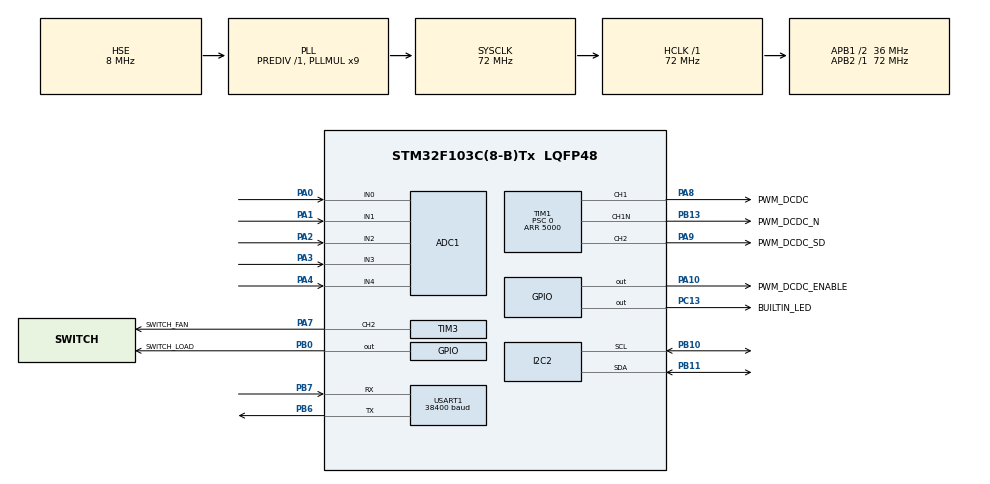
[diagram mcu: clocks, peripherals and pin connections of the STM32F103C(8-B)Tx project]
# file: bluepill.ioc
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ADC1.Channel-2\#ChannelRegularConversion=ADC_CHANNEL_0
ADC1.Channel-3\#ChannelRegularConversion=ADC_CHANNEL_1
ADC1.Channel-4\#ChannelRegularConversion=ADC_CHANNEL_2
ADC1.Channel-5\#ChannelRegularConversion=ADC_CHANNEL_3
ADC1.Channel-6\#ChannelRegularConversion=ADC_CHANNEL_4
ADC1.ContinuousConvMode=ENABLE
ADC1.NbrOfConversion=5
ADC1.NbrOfConversionFlag=1
ADC1.Rank-2\#ChannelRegularConversion=1
ADC1.Rank-3\#ChannelRegularConversion=2
ADC1.Rank-4\#ChannelRegularConversion=3
ADC1.Rank-5\#ChannelRegularConversion=4
ADC1.Rank-6\#ChannelRegularConversion=5
ADC1.SamplingTime-2\#ChannelRegularConversion=ADC_SAMPLETIME_239CYCLES_5
ADC1.SamplingTime-3\#ChannelRegularConversion=ADC_SAMPLETIME_239CYCLES_5
ADC1.SamplingTime-4\#ChannelRegularConversion=ADC_SAMPLETIME_239CYCLES_5
ADC1.SamplingTime-5\#ChannelRegularConversion=ADC_SAMPLETIME_239CYCLES_5
ADC1.SamplingTime-6\#ChannelRegularConversion=ADC_SAMPLETIME_239CYCLES_5
ADC1.master=1
Dma.ADC1.0.Direction=DMA_PERIPH_TO_MEMORY
Dma.ADC1.0.Instance=DMA1_Channel1
Dma.ADC1.0.MemDataAlignment=DMA_MDATAALIGN_HALFWORD
Dma.ADC1.0.MemInc=DMA_MINC_ENABLE
Dma.ADC1.0.Mode=DMA_CIRCULAR
Dma.ADC1.0.PeriphDataAlignment=DMA_PDATAALIGN_HALFWORD
Dma.ADC1.0.PeriphInc=DMA_PINC_DISABLE
Dma.ADC1.0.Priority=DMA_PRIORITY_LOW
Dma.Request0=ADC1
Mcu.Family=STM32F1
Mcu.Name=STM32F103C(8-B)Tx
Mcu.Package=LQFP48
NVIC.DMA1_Channel1_IRQn=true\:0\:0\:false\:false\:true\:false\:true\:true
NVIC.PriorityGroup=NVIC_PRIORITYGROUP_4
NVIC.TIM2_IRQn=true\:0\:0\:false\:false\:true\:true\:true\:true
NVIC.USART1_IRQn=true\:0\:0\:false\:false\:true\:true\:true\:true
PA0-WKUP.Signal=ADCx_IN0
PA1.Signal=ADCx_IN1
PA10.GPIO_Label=PWM_DCDC_ENABLE
PA10.Signal=GPIO_Output
PA13.Mode=Serial_Wire
PA13.Signal=SYS_JTMS-SWDIO
PA14.Mode=Serial_Wire
PA14.Signal=SYS_JTCK-SWCLK
PA2.Signal=ADCx_IN2
PA3.Signal=ADCx_IN3
PA4.Signal=ADCx_IN4
PA7.GPIO_Label=SWITCH_FAN
PA7.Signal=S_TIM3_CH2
PA8.GPIO_Label=PWM_DCDC
PA8.Signal=S_TIM1_CH1
PA9.GPIO_Label=PWM_DCDC_SD
PA9.Signal=S_TIM1_CH2
PB0.GPIO_Label=SWITCH_LOAD
PB0.Signal=GPIO_Output
PB10.GPIO_Pu=GPIO_PULLUP
PB10.Mode=I2C
PB10.Signal=I2C2_SCL
PB11.GPIO_Pu=GPIO_PULLUP
PB11.Mode=I2C
PB11.Signal=I2C2_SDA
PB13.GPIO_Label=PWM_DCDC_N
PB13.Mode=PWM Generation1 CH1 CH1N
PB13.Signal=TIM1_CH1N
PB6.Mode=Asynchronous
PB6.Signal=USART1_TX
PB7.Mode=Asynchronous
PB7.Signal=USART1_RX
PC13-TAMPER-RTC.GPIO_Label=BUILTIN_LED
PC13-TAMPER-RTC.Signal=GPIO_Output
PC14-OSC32_IN.Mode=LSE-External-Oscillator
PC14-OSC32_IN.Signal=RCC_OSC32_IN
PC15-OSC32_OUT.Mode=LSE-External-Oscillator
PC15-OSC32_OUT.Signal=RCC_OSC32_OUT
PD0-OSC_IN.Mode=HSE-External-Oscillator
PD0-OSC_IN.Signal=RCC_OSC_IN
PD1-OSC_OUT.Mode=HSE-External-Oscillator
PD1-OSC_OUT.Signal=RCC_OSC_OUT
ProjectManager.HeapSize=0x200
ProjectManager.StackSize=0x400
ProjectManager.TargetToolchain=Makefile
RCC.ADCPresc=RCC_ADCPCLK2_DIV6
RCC.AHBFreq_Value=72000000
RCC.APB1CLKDivider=RCC_HCLK_DIV2
RCC.APB1Freq_Value=36000000
RCC.APB1TimFreq_Value=72000000
RCC.APB2Freq_Value=72000000
RCC.APB2TimFreq_Value=72000000
RCC.HCLKFreq_Value=72000000
RCC.PLLMUL=RCC_PLL_MUL9
RCC.PLLSourceVirtual=RCC_PLLSOURCE_HSE
RCC.RTCClockSelection=RCC_RTCCLKSOURCE_LSE
RCC.SYSCLKFreq_VALUE=72000000
RCC.SYSCLKSource=RCC_SYSCLKSOURCE_PLLCLK
RCC.USBFreq_Value=48000000
RCC.USBPrescaler=RCC_USBCLKSOURCE_PLL_DIV1_5
SH.ADCx_IN0.0=ADC1_IN0,IN0
SH.ADCx_IN1.0=ADC1_IN1,IN1
SH.ADCx_IN2.0=ADC1_IN2,IN2
SH.ADCx_IN3.0=ADC1_IN3,IN3
SH.ADCx_IN4.0=ADC1_IN4,IN4
SH.S_TIM1_CH1.0=TIM1_CH1,PWM Generation1 CH1 CH1N
SH.S_TIM1_CH2.0=TIM1_CH2,PWM Generation2 CH2
SH.S_TIM3_CH2.0=TIM3_CH2,PWM Generation2 CH2
TIM1.AutomaticOutput=TIM_AUTOMATICOUTPUT_DISABLE
TIM1.Channel-PWM\ Generation1\ CH1\ CH1N=TIM_CHANNEL_1
TIM1.Channel-PWM\ Generation2\ CH2=TIM_CHANNEL_2
TIM1.OCIdleState_1=TIM_OCIDLESTATE_RESET
TIM1.OCPolarity_1=TIM_OCPOLARITY_HIGH
TIM1.Period=5000
TIM1.Prescaler=0
TIM2.Period=20000
TIM2.Prescaler=71
TIM3.Channel-PWM\ Generation2\ CH2=TIM_CHANNEL_2
TIM3.Period=255
USART1.BaudRate=38400
USART1.VirtualMode=VM_ASYNC
VP_RTC_No_RTC_Output.Mode=RTC_OUT_NO
VP_RTC_VS_RTC_Activate.Mode=RTC_Enabled
VP_RTC_VS_RTC_Calendar.Mode=RTC_Calendar
VP_TIM1_VS_ClockSourceINT.Mode=Internal
VP_TIM2_VS_ClockSourceINT.Mode=Internal
VP_TIM3_VS_ClockSourceINT.Mode=Internal
board=custom

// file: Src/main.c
/* USER CODE BEGIN Header */
/**
  ******************************************************************************
  * @file           : main.c
  * @brief          : Main program body
  ******************************************************************************
  * @attention
  *
  * <h2><center>&copy; Copyright (c) 2019 STMicroelectronics.
  * All rights reserved.</center></h2>
  *
  * This software component is licensed by ST under BSD 3-Clause license,
  * the "License"; You may not use this file except in compliance with the
  * License. You may obtain a copy of the License at:
  *                        opensource.org/licenses/BSD-3-Clause
  *
  ******************************************************************************
  */
/* USER CODE END Header */
#include "main.h"

/* USER CODE BEGIN Includes */
#include "solar.h"
/* USER CODE END Includes */

ADC_HandleTypeDef hadc1;
DMA_HandleTypeDef hdma_adc1;

I2C_HandleTypeDef hi2c2;

RTC_HandleTypeDef hrtc;

TIM_HandleTypeDef htim1;
TIM_HandleTypeDef htim2;
TIM_HandleTypeDef htim3;

UART_HandleTypeDef huart1;

void SystemClock_Config(void);
static void MX_GPIO_Init(void);
static void MX_DMA_Init(void);
static void MX_RTC_Init(void);
static void MX_USART1_UART_Init(void);
static void MX_ADC1_Init(void);
static void MX_TIM1_Init(void);
static void MX_TIM2_Init(void);
static void MX_I2C2_Init(void);
static void MX_TIM3_Init(void);

int main(void)
{

  /* MCU Configuration--------------------------------------------------------*/

  /* Reset of all peripherals, Initializes the Flash interface and the Systick. */
  HAL_Init();

  /* Configure the system clock */
  SystemClock_Config();

  /* Initialize all configured peripherals */
  MX_GPIO_Init();
  MX_DMA_Init();
  MX_RTC_Init();
  MX_USART1_UART_Init();
  MX_ADC1_Init();
  MX_TIM1_Init();
  MX_TIM2_Init();
  MX_I2C2_Init();
  MX_TIM3_Init();

  /* Infinite loop */
  /* USER CODE BEGIN WHILE */
  solar_main();
  while (1)
  {
    /* USER CODE END WHILE */

  }
}

void SystemClock_Config(void)
{
  RCC_OscInitTypeDef RCC_OscInitStruct = {0};
  RCC_ClkInitTypeDef RCC_ClkInitStruct = {0};
  RCC_PeriphCLKInitTypeDef PeriphClkInit = {0};

  /** Initializes the RCC Oscillators according to the specified parameters
  * in the RCC_OscInitTypeDef structure.
  */
  RCC_OscInitStruct.OscillatorType = RCC_OSCILLATORTYPE_HSE|RCC_OSCILLATORTYPE_LSE;
  RCC_OscInitStruct.HSEState = RCC_HSE_ON;
  RCC_OscInitStruct.HSEPredivValue = RCC_HSE_PREDIV_DIV1;
  RCC_OscInitStruct.LSEState = RCC_LSE_ON;
  RCC_OscInitStruct.HSIState = RCC_HSI_ON;
  RCC_OscInitStruct.PLL.PLLState = RCC_PLL_ON;
  RCC_OscInitStruct.PLL.PLLSource = RCC_PLLSOURCE_HSE;
  RCC_OscInitStruct.PLL.PLLMUL = RCC_PLL_MUL9;
  if (HAL_RCC_OscConfig(&RCC_OscInitStruct) != HAL_OK)
  {
    Error_Handler();
  }

  /** Initializes the CPU, AHB and APB buses clocks
  */
  RCC_ClkInitStruct.ClockType = RCC_CLOCKTYPE_HCLK|RCC_CLOCKTYPE_SYSCLK
                              |RCC_CLOCKTYPE_PCLK1|RCC_CLOCKTYPE_PCLK2;
  RCC_ClkInitStruct.SYSCLKSource = RCC_SYSCLKSOURCE_PLLCLK;
  RCC_ClkInitStruct.AHBCLKDivider = RCC_SYSCLK_DIV1;
  RCC_ClkInitStruct.APB1CLKDivider = RCC_HCLK_DIV2;
  RCC_ClkInitStruct.APB2CLKDivider = RCC_HCLK_DIV1;

  if (HAL_RCC_ClockConfig(&RCC_ClkInitStruct, FLASH_LATENCY_2) != HAL_OK)
  {
    Error_Handler();
  }
  PeriphClkInit.PeriphClockSelection = RCC_PERIPHCLK_RTC|RCC_PERIPHCLK_ADC;
  PeriphClkInit.RTCClockSelection = RCC_RTCCLKSOURCE_LSE;
  PeriphClkInit.AdcClockSelection = RCC_ADCPCLK2_DIV6;
  if (HAL_RCCEx_PeriphCLKConfig(&PeriphClkInit) != HAL_OK)
  {
    Error_Handler();
  }
}

static void MX_ADC1_Init(void)
{

  ADC_ChannelConfTypeDef sConfig = {0};

  /** Common config
  */
  hadc1.Instance = ADC1;
  hadc1.Init.ScanConvMode = ADC_SCAN_ENABLE;
  hadc1.Init.ContinuousConvMode = ENABLE;
  hadc1.Init.DiscontinuousConvMode = DISABLE;
  hadc1.Init.ExternalTrigConv = ADC_SOFTWARE_START;
  hadc1.Init.DataAlign = ADC_DATAALIGN_RIGHT;
  hadc1.Init.NbrOfConversion = 5;
  if (HAL_ADC_Init(&hadc1) != HAL_OK)
  {
    Error_Handler();
  }

  /** Configure Regular Channel
  */
  sConfig.Channel = ADC_CHANNEL_0;
  sConfig.Rank = ADC_REGULAR_RANK_1;
  sConfig.SamplingTime = ADC_SAMPLETIME_239CYCLES_5;
  if (HAL_ADC_ConfigChannel(&hadc1, &sConfig) != HAL_OK)
  {
    Error_Handler();
  }

  /** Configure Regular Channel
  */
  sConfig.Channel = ADC_CHANNEL_1;
  sConfig.Rank = ADC_REGULAR_RANK_2;
  if (HAL_ADC_ConfigChannel(&hadc1, &sConfig) != HAL_OK)
  {
    Error_Handler();
  }

  /** Configure Regular Channel
  */
  sConfig.Channel = ADC_CHANNEL_2;
  sConfig.Rank = ADC_REGULAR_RANK_3;
  if (HAL_ADC_ConfigChannel(&hadc1, &sConfig) != HAL_OK)
  {
    Error_Handler();
  }

  /** Configure Regular Channel
  */
  sConfig.Channel = ADC_CHANNEL_3;
  sConfig.Rank = ADC_REGULAR_RANK_4;
  if (HAL_ADC_ConfigChannel(&hadc1, &sConfig) != HAL_OK)
  {
    Error_Handler();
  }

  /** Configure Regular Channel
  */
  sConfig.Channel = ADC_CHANNEL_4;
  sConfig.Rank = ADC_REGULAR_RANK_5;
  if (HAL_ADC_ConfigChannel(&hadc1, &sConfig) != HAL_OK)
  {
    Error_Handler();
  }

}

static void MX_I2C2_Init(void)
{

  hi2c2.Instance = I2C2;
  hi2c2.Init.ClockSpeed = 100000;
  hi2c2.Init.DutyCycle = I2C_DUTYCYCLE_2;
  hi2c2.Init.OwnAddress1 = 0;
  hi2c2.Init.AddressingMode = I2C_ADDRESSINGMODE_7BIT;
  hi2c2.Init.DualAddressMode = I2C_DUALADDRESS_DISABLE;
  hi2c2.Init.OwnAddress2 = 0;
  hi2c2.Init.GeneralCallMode = I2C_GENERALCALL_DISABLE;
  hi2c2.Init.NoStretchMode = I2C_NOSTRETCH_DISABLE;
  if (HAL_I2C_Init(&hi2c2) != HAL_OK)
  {
    Error_Handler();
  }

}

static void MX_RTC_Init(void)
{

  RTC_TimeTypeDef sTime = {0};
  RTC_DateTypeDef DateToUpdate = {0};

  /** Initialize RTC Only
  */
  hrtc.Instance = RTC;
  hrtc.Init.AsynchPrediv = RTC_AUTO_1_SECOND;
  hrtc.Init.OutPut = RTC_OUTPUTSOURCE_NONE;
  if (HAL_RTC_Init(&hrtc) != HAL_OK)
  {
    Error_Handler();
  }

  /** Initialize RTC and set the Time and Date
  */
  sTime.Hours = 0x0;
  sTime.Minutes = 0x0;
  sTime.Seconds = 0x0;

  if (HAL_RTC_SetTime(&hrtc, &sTime, RTC_FORMAT_BCD) != HAL_OK)
  {
    Error_Handler();
  }
  DateToUpdate.WeekDay = RTC_WEEKDAY_MONDAY;
  DateToUpdate.Month = RTC_MONTH_JANUARY;
  DateToUpdate.Date = 0x1;
  DateToUpdate.Year = 0x0;

  if (HAL_RTC_SetDate(&hrtc, &DateToUpdate, RTC_FORMAT_BCD) != HAL_OK)
  {
    Error_Handler();
  }

}

static void MX_TIM1_Init(void)
{

  TIM_ClockConfigTypeDef sClockSourceConfig = {0};
  TIM_MasterConfigTypeDef sMasterConfig = {0};
  TIM_OC_InitTypeDef sConfigOC = {0};
  TIM_BreakDeadTimeConfigTypeDef sBreakDeadTimeConfig = {0};

  htim1.Instance = TIM1;
  htim1.Init.Prescaler = 0;
  htim1.Init.CounterMode = TIM_COUNTERMODE_UP;
  htim1.Init.Period = 5000;
  htim1.Init.ClockDivision = TIM_CLOCKDIVISION_DIV1;
  htim1.Init.RepetitionCounter = 0;
  htim1.Init.AutoReloadPreload = TIM_AUTORELOAD_PRELOAD_DISABLE;
  if (HAL_TIM_Base_Init(&htim1) != HAL_OK)
  {
    Error_Handler();
  }
  sClockSourceConfig.ClockSource = TIM_CLOCKSOURCE_INTERNAL;
  if (HAL_TIM_ConfigClockSource(&htim1, &sClockSourceConfig) != HAL_OK)
  {
    Error_Handler();
  }
  if (HAL_TIM_PWM_Init(&htim1) != HAL_OK)
  {
    Error_Handler();
  }
  sMasterConfig.MasterOutputTrigger = TIM_TRGO_RESET;
  sMasterConfig.MasterSlaveMode = TIM_MASTERSLAVEMODE_DISABLE;
  if (HAL_TIMEx_MasterConfigSynchronization(&htim1, &sMasterConfig) != HAL_OK)
  {
    Error_Handler();
  }
  sConfigOC.OCMode = TIM_OCMODE_PWM1;
  sConfigOC.Pulse = 0;
  sConfigOC.OCPolarity = TIM_OCPOLARITY_HIGH;
  sConfigOC.OCNPolarity = TIM_OCNPOLARITY_HIGH;
  sConfigOC.OCFastMode = TIM_OCFAST_DISABLE;
  sConfigOC.OCIdleState = TIM_OCIDLESTATE_RESET;
  sConfigOC.OCNIdleState = TIM_OCNIDLESTATE_RESET;
  if (HAL_TIM_PWM_ConfigChannel(&htim1, &sConfigOC, TIM_CHANNEL_1) != HAL_OK)
  {
    Error_Handler();
  }
  if (HAL_TIM_PWM_ConfigChannel(&htim1, &sConfigOC, TIM_CHANNEL_2) != HAL_OK)
  {
    Error_Handler();
  }
  sBreakDeadTimeConfig.OffStateRunMode = TIM_OSSR_DISABLE;
  sBreakDeadTimeConfig.OffStateIDLEMode = TIM_OSSI_DISABLE;
  sBreakDeadTimeConfig.LockLevel = TIM_LOCKLEVEL_OFF;
  sBreakDeadTimeConfig.DeadTime = 0;
  sBreakDeadTimeConfig.BreakState = TIM_BREAK_DISABLE;
  sBreakDeadTimeConfig.BreakPolarity = TIM_BREAKPOLARITY_HIGH;
  sBreakDeadTimeConfig.AutomaticOutput = TIM_AUTOMATICOUTPUT_DISABLE;
  if (HAL_TIMEx_ConfigBreakDeadTime(&htim1, &sBreakDeadTimeConfig) != HAL_OK)
  {
    Error_Handler();
  }
  HAL_TIM_MspPostInit(&htim1);

}

static void MX_TIM2_Init(void)
{

  TIM_ClockConfigTypeDef sClockSourceConfig = {0};
  TIM_MasterConfigTypeDef sMasterConfig = {0};

  htim2.Instance = TIM2;
  htim2.Init.Prescaler = 71;
  htim2.Init.CounterMode = TIM_COUNTERMODE_UP;
  htim2.Init.Period = 20000;
  htim2.Init.ClockDivision = TIM_CLOCKDIVISION_DIV1;
  htim2.Init.AutoReloadPreload = TIM_AUTORELOAD_PRELOAD_DISABLE;
  if (HAL_TIM_Base_Init(&htim2) != HAL_OK)
  {
    Error_Handler();
  }
  sClockSourceConfig.ClockSource = TIM_CLOCKSOURCE_INTERNAL;
  if (HAL_TIM_ConfigClockSource(&htim2, &sClockSourceConfig) != HAL_OK)
  {
    Error_Handler();
  }
  sMasterConfig.MasterOutputTrigger = TIM_TRGO_RESET;
  sMasterConfig.MasterSlaveMode = TIM_MASTERSLAVEMODE_DISABLE;
  if (HAL_TIMEx_MasterConfigSynchronization(&htim2, &sMasterConfig) != HAL_OK)
  {
    Error_Handler();
  }

}

static void MX_TIM3_Init(void)
{

  TIM_ClockConfigTypeDef sClockSourceConfig = {0};
  TIM_MasterConfigTypeDef sMasterConfig = {0};
  TIM_OC_InitTypeDef sConfigOC = {0};

  htim3.Instance = TIM3;
  htim3.Init.Prescaler = 0;
  htim3.Init.CounterMode = TIM_COUNTERMODE_UP;
  htim3.Init.Period = 255;
  htim3.Init.ClockDivision = TIM_CLOCKDIVISION_DIV1;
  htim3.Init.AutoReloadPreload = TIM_AUTORELOAD_PRELOAD_DISABLE;
  if (HAL_TIM_Base_Init(&htim3) != HAL_OK)
  {
    Error_Handler();
  }
  sClockSourceConfig.ClockSource = TIM_CLOCKSOURCE_INTERNAL;
  if (HAL_TIM_ConfigClockSource(&htim3, &sClockSourceConfig) != HAL_OK)
  {
    Error_Handler();
  }
  if (HAL_TIM_PWM_Init(&htim3) != HAL_OK)
  {
    Error_Handler();
  }
  sMasterConfig.MasterOutputTrigger = TIM_TRGO_RESET;
  sMasterConfig.MasterSlaveMode = TIM_MASTERSLAVEMODE_DISABLE;
  if (HAL_TIMEx_MasterConfigSynchronization(&htim3, &sMasterConfig) != HAL_OK)
  {
    Error_Handler();
  }
  sConfigOC.OCMode = TIM_OCMODE_PWM1;
  sConfigOC.Pulse = 0;
  sConfigOC.OCPolarity = TIM_OCPOLARITY_HIGH;
  sConfigOC.OCFastMode = TIM_OCFAST_DISABLE;
  if (HAL_TIM_PWM_ConfigChannel(&htim3, &sConfigOC, TIM_CHANNEL_2) != HAL_OK)
  {
    Error_Handler();
  }
  HAL_TIM_MspPostInit(&htim3);

}

static void MX_USART1_UART_Init(void)
{

  huart1.Instance = USART1;
  huart1.Init.BaudRate = 38400;
  huart1.Init.WordLength = UART_WORDLENGTH_8B;
  huart1.Init.StopBits = UART_STOPBITS_1;
  huart1.Init.Parity = UART_PARITY_NONE;
  huart1.Init.Mode = UART_MODE_TX_RX;
  huart1.Init.HwFlowCtl = UART_HWCONTROL_NONE;
  huart1.Init.OverSampling = UART_OVERSAMPLING_16;
  if (HAL_UART_Init(&huart1) != HAL_OK)
  {
    Error_Handler();
  }

}

static void MX_DMA_Init(void)
{

  /* DMA controller clock enable */
  __HAL_RCC_DMA1_CLK_ENABLE();

  /* DMA interrupt init */
  /* DMA1_Channel1_IRQn interrupt configuration */
  HAL_NVIC_SetPriority(DMA1_Channel1_IRQn, 0, 0);
  HAL_NVIC_EnableIRQ(DMA1_Channel1_IRQn);

}

static void MX_GPIO_Init(void)
{
  GPIO_InitTypeDef GPIO_InitStruct = {0};

  /* GPIO Ports Clock Enable */
  __HAL_RCC_GPIOC_CLK_ENABLE();
  __HAL_RCC_GPIOD_CLK_ENABLE();
  __HAL_RCC_GPIOA_CLK_ENABLE();
  __HAL_RCC_GPIOB_CLK_ENABLE();

  /*Configure GPIO pin Output Level */
  HAL_GPIO_WritePin(BUILTIN_LED_GPIO_Port, BUILTIN_LED_Pin, GPIO_PIN_RESET);

  /*Configure GPIO pin Output Level */
  HAL_GPIO_WritePin(SWITCH_LOAD_GPIO_Port, SWITCH_LOAD_Pin, GPIO_PIN_RESET);

  /*Configure GPIO pin Output Level */
  HAL_GPIO_WritePin(PWM_DCDC_ENABLE_GPIO_Port, PWM_DCDC_ENABLE_Pin, GPIO_PIN_RESET);

  /*Configure GPIO pin : BUILTIN_LED_Pin */
  GPIO_InitStruct.Pin = BUILTIN_LED_Pin;
  GPIO_InitStruct.Mode = GPIO_MODE_OUTPUT_PP;
  GPIO_InitStruct.Pull = GPIO_NOPULL;
  GPIO_InitStruct.Speed = GPIO_SPEED_FREQ_LOW;
  HAL_GPIO_Init(BUILTIN_LED_GPIO_Port, &GPIO_InitStruct);

  /*Configure GPIO pin : SWITCH_LOAD_Pin */
  GPIO_InitStruct.Pin = SWITCH_LOAD_Pin;
  GPIO_InitStruct.Mode = GPIO_MODE_OUTPUT_PP;
  GPIO_InitStruct.Pull = GPIO_NOPULL;
  GPIO_InitStruct.Speed = GPIO_SPEED_FREQ_LOW;
  HAL_GPIO_Init(SWITCH_LOAD_GPIO_Port, &GPIO_InitStruct);

  /*Configure GPIO pin : PWM_DCDC_ENABLE_Pin */
  GPIO_InitStruct.Pin = PWM_DCDC_ENABLE_Pin;
  GPIO_InitStruct.Mode = GPIO_MODE_OUTPUT_PP;
  GPIO_InitStruct.Pull = GPIO_NOPULL;
  GPIO_InitStruct.Speed = GPIO_SPEED_FREQ_LOW;
  HAL_GPIO_Init(PWM_DCDC_ENABLE_GPIO_Port, &GPIO_InitStruct);

}

void Error_Handler(void)
{
}
